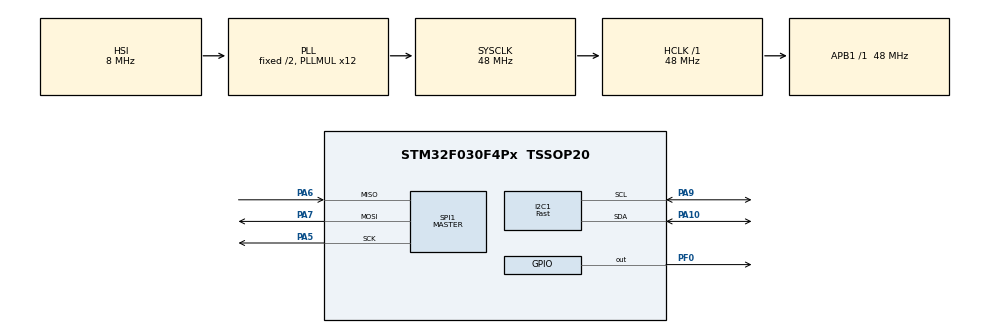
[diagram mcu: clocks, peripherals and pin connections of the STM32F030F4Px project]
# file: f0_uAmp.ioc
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I2C1.I2C_Speed_Mode=I2C_Fast
I2C1.OwnAddress=0x40
I2C1.Timing=0x0000020B
Mcu.Family=STM32F0
Mcu.Name=STM32F030F4Px
Mcu.Package=TSSOP20
NVIC.I2C1_IRQn=true\:0\:0\:false
PA10.Mode=I2C
PA10.Signal=I2C1_SDA
PA13.Mode=Serial-WireDebug
PA13.Signal=SYS_SWDIO
PA14.Mode=Serial-WireDebug
PA14.Signal=SYS_SWCLK
PA5.Mode=Full_Duplex_Master
PA5.Signal=SPI1_SCK
PA6.Mode=Full_Duplex_Master
PA6.Signal=SPI1_MISO
PA7.Mode=Full_Duplex_Master
PA7.Signal=SPI1_MOSI
PA9.Mode=I2C
PA9.Signal=I2C1_SCL
PF0-OSC_IN.Signal=GPIO_Output
ProjectManager.TargetToolchain=MDK-ARM V5
RCC.AHBFreq_Value=48000000
RCC.APB1Freq_Value=48000000
RCC.APB1TimFreq_Value=48000000
RCC.HCLKFreq_Value=48000000
RCC.PLLMUL=RCC_PLL_MUL12
RCC.SYSCLKFreq_VALUE=48000000
RCC.SYSCLKSource=RCC_SYSCLKSOURCE_PLLCLK
SPI1.BaudRatePrescaler-Full_Duplex_Master=SPI_BAUDRATEPRESCALER_4
SPI1.CalculateBaudRate-Full_Duplex_Master=12.0 MBits/s
SPI1.Mode=SPI_MODE_MASTER
SPI1.Mode-Full_Duplex_Master=SPI_MODE_MASTER

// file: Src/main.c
/**
  ******************************************************************************
  * File Name          : main.c
  * Description        : Main program body
  ******************************************************************************
  *
  * COPYRIGHT(c) 2015 STMicroelectronics
  *
  * Redistribution and use in source and binary forms, with or without modification,
  * are permitted provided that the following conditions are met:
  *   1. Redistributions of source code must retain the above copyright notice,
  *      this list of conditions and the following disclaimer.
  *   2. Redistributions in binary form must reproduce the above copyright notice,
  *      this list of conditions and the following disclaimer in the documentation
  *      and/or other materials provided with the distribution.
  *   3. Neither the name of STMicroelectronics nor the names of its contributors
  *      may be used to endorse or promote products derived from this software
  *      without specific prior written permission.
  *
  * THIS SOFTWARE IS PROVIDED BY THE COPYRIGHT HOLDERS AND CONTRIBUTORS "AS IS"
  * AND ANY EXPRESS OR IMPLIED WARRANTIES, INCLUDING, BUT NOT LIMITED TO, THE
  * IMPLIED WARRANTIES OF MERCHANTABILITY AND FITNESS FOR A PARTICULAR PURPOSE ARE
  * DISCLAIMED. IN NO EVENT SHALL THE COPYRIGHT HOLDER OR CONTRIBUTORS BE LIABLE
  * FOR ANY DIRECT, INDIRECT, INCIDENTAL, SPECIAL, EXEMPLARY, OR CONSEQUENTIAL
  * DAMAGES (INCLUDING, BUT NOT LIMITED TO, PROCUREMENT OF SUBSTITUTE GOODS OR
  * SERVICES; LOSS OF USE, DATA, OR PROFITS; OR BUSINESS INTERRUPTION) HOWEVER
  * CAUSED AND ON ANY THEORY OF LIABILITY, WHETHER IN CONTRACT, STRICT LIABILITY,
  * OR TORT (INCLUDING NEGLIGENCE OR OTHERWISE) ARISING IN ANY WAY OUT OF THE USE
  * OF THIS SOFTWARE, EVEN IF ADVISED OF THE POSSIBILITY OF SUCH DAMAGE.
  *
  ******************************************************************************
  */
#include "stm32f0xx_hal.h"

/* USER CODE BEGIN Includes */

#include "lib_ina219.h"

/* USER CODE END Includes */

I2C_HandleTypeDef hi2c1;

SPI_HandleTypeDef hspi1;

/* USER CODE BEGIN PV */

float data, raw ;

/* USER CODE END PV */

void SystemClock_Config(void);
static void MX_GPIO_Init(void);
static void MX_I2C1_Init(void);
static void MX_SPI1_Init(void);

int main(void)
{

  /* USER CODE BEGIN 1 */
	raw = 0;
	data = 0;
  /* USER CODE END 1 */

  /* MCU Configuration----------------------------------------------------------*/

  /* Reset of all peripherals, Initializes the Flash interface and the Systick. */
  HAL_Init();

  /* Configure the system clock */
  SystemClock_Config();

  /* Initialize all configured peripherals */
  MX_GPIO_Init();
  MX_I2C1_Init();
  MX_SPI1_Init();

  /* USER CODE BEGIN 2 */

	HAL_Delay(100);

	ina219_SetCalibration_16V_80mA();

  /* USER CODE END 2 */

  /* Infinite loop */
  while (1)
  {

  /* USER CODE BEGIN 3 */
		static float data_prev;
		HAL_GPIO_TogglePin(GPIOF, GPIO_PIN_0);

		HAL_Delay(1);
		raw = ina219_getCurrent_mA();
		data_prev = data;
		data = data_prev +0.01f*(raw-data_prev);
  }
  /* USER CODE END 3 */

}

/** System Clock Configuration
*/
void SystemClock_Config(void)
{

  RCC_OscInitTypeDef RCC_OscInitStruct;
  RCC_ClkInitTypeDef RCC_ClkInitStruct;
  RCC_PeriphCLKInitTypeDef PeriphClkInit;

  RCC_OscInitStruct.OscillatorType = RCC_OSCILLATORTYPE_HSI;
  RCC_OscInitStruct.HSIState = RCC_HSI_ON;
  RCC_OscInitStruct.HSICalibrationValue = 16;
  RCC_OscInitStruct.PLL.PLLState = RCC_PLL_ON;
  RCC_OscInitStruct.PLL.PLLSource = RCC_PLLSOURCE_HSI;
  RCC_OscInitStruct.PLL.PLLMUL = RCC_PLL_MUL12;
  RCC_OscInitStruct.PLL.PREDIV = RCC_PREDIV_DIV1;
  HAL_RCC_OscConfig(&RCC_OscInitStruct);

  RCC_ClkInitStruct.ClockType = RCC_CLOCKTYPE_SYSCLK;
  RCC_ClkInitStruct.SYSCLKSource = RCC_SYSCLKSOURCE_PLLCLK;
  RCC_ClkInitStruct.AHBCLKDivider = RCC_SYSCLK_DIV1;
  RCC_ClkInitStruct.APB1CLKDivider = RCC_HCLK_DIV1;
  HAL_RCC_ClockConfig(&RCC_ClkInitStruct, FLASH_LATENCY_1);

  PeriphClkInit.PeriphClockSelection = RCC_PERIPHCLK_I2C1;
  PeriphClkInit.I2c1ClockSelection = RCC_I2C1CLKSOURCE_HSI;
  HAL_RCCEx_PeriphCLKConfig(&PeriphClkInit);

  HAL_SYSTICK_Config(HAL_RCC_GetHCLKFreq()/1000);

  HAL_SYSTICK_CLKSourceConfig(SYSTICK_CLKSOURCE_HCLK);

}

/* I2C1 init function */
void MX_I2C1_Init(void)
{

  hi2c1.Instance = I2C1;
  hi2c1.Init.Timing = 0x0000020B;
  hi2c1.Init.OwnAddress1 = 128;
  hi2c1.Init.AddressingMode = I2C_ADDRESSINGMODE_7BIT;
  hi2c1.Init.DualAddressMode = I2C_DUALADDRESS_DISABLED;
  hi2c1.Init.OwnAddress2 = 0;
  hi2c1.Init.OwnAddress2Masks = I2C_OA2_NOMASK;
  hi2c1.Init.GeneralCallMode = I2C_GENERALCALL_DISABLED;
  hi2c1.Init.NoStretchMode = I2C_NOSTRETCH_DISABLED;
  HAL_I2C_Init(&hi2c1);

    /**Configure Analogue filter
    */
  HAL_I2CEx_AnalogFilter_Config(&hi2c1, I2C_ANALOGFILTER_ENABLED);

}

/* SPI1 init function */
void MX_SPI1_Init(void)
{

  hspi1.Instance = SPI1;
  hspi1.Init.Mode = SPI_MODE_MASTER;
  hspi1.Init.Direction = SPI_DIRECTION_2LINES;
  hspi1.Init.DataSize = SPI_DATASIZE_4BIT;
  hspi1.Init.CLKPolarity = SPI_POLARITY_LOW;
  hspi1.Init.CLKPhase = SPI_PHASE_1EDGE;
  hspi1.Init.NSS = SPI_NSS_SOFT;
  hspi1.Init.BaudRatePrescaler = SPI_BAUDRATEPRESCALER_4;
  hspi1.Init.FirstBit = SPI_FIRSTBIT_MSB;
  hspi1.Init.TIMode = SPI_TIMODE_DISABLED;
  hspi1.Init.CRCCalculation = SPI_CRCCALCULATION_DISABLED;
  hspi1.Init.CRCPolynomial = 10;
  hspi1.Init.CRCLength = SPI_CRC_LENGTH_DATASIZE;
  hspi1.Init.NSSPMode = SPI_NSS_PULSE_ENABLED;
  HAL_SPI_Init(&hspi1);

}

/** Configure pins as
        * Analog
        * Input
        * Output
        * EVENT_OUT
        * EXTI
*/
void MX_GPIO_Init(void)
{

  GPIO_InitTypeDef GPIO_InitStruct;

  /* GPIO Ports Clock Enable */
  __GPIOF_CLK_ENABLE();
  __GPIOA_CLK_ENABLE();

  /*Configure GPIO pin : PF0 */
  GPIO_InitStruct.Pin = GPIO_PIN_0;
  GPIO_InitStruct.Mode = GPIO_MODE_OUTPUT_PP;
  GPIO_InitStruct.Pull = GPIO_NOPULL;
  GPIO_InitStruct.Speed = GPIO_SPEED_LOW;
  HAL_GPIO_Init(GPIOF, &GPIO_InitStruct);

}

/************************ (C) COPYRIGHT STMicroelectronics *****END OF FILE****/
